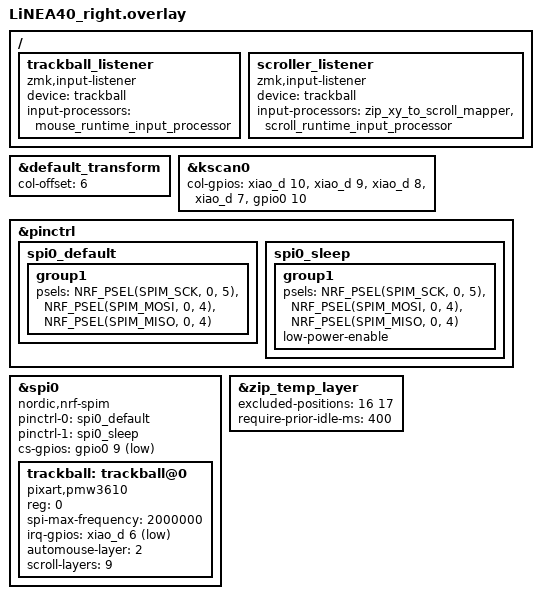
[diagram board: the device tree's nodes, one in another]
#include "LiNEA40.dtsi"
#include <input/processors.dtsi>
#include <input/processors/runtime-input-processor.dtsi>
#include <behaviors/battery_history_request.dtsi>

&default_transform {
    col-offset = <6>;
};

&kscan0 {
    col-gpios
        = <&xiao_d 10 GPIO_ACTIVE_HIGH> // col0-D10
        , <&xiao_d 9 GPIO_ACTIVE_HIGH>  // col1-D9
        , <&xiao_d 8 GPIO_ACTIVE_HIGH>  // col2-D8
        , <&xiao_d 7 GPIO_ACTIVE_HIGH>  // col3-D7
        , <&gpio0 10 GPIO_ACTIVE_HIGH>  // col4-D10 (修正済み)
        ; 
}; 

&pinctrl {
    spi0_default: spi0_default {
        group1 {
            psels = <NRF_PSEL(SPIM_SCK, 0, 5)>   // SCLK-D5
                  , <NRF_PSEL(SPIM_MOSI, 0, 4)>  // SDIO-D4
                  , <NRF_PSEL(SPIM_MISO, 0, 4)>  // SDIO-D4
                  ;
        };
    };

    spi0_sleep: spi0_sleep {
        group1 {
            psels = <NRF_PSEL(SPIM_SCK, 0, 5)>   // SCLK-D5
                  , <NRF_PSEL(SPIM_MOSI, 0, 4)>  // SDIO-D4
                  , <NRF_PSEL(SPIM_MISO, 0, 4)>  // SDIO-D4
                  ;
            low-power-enable;
        };
    };
};

&spi0 {
    status = "okay";
    compatible = "nordic,nrf-spim";
    pinctrl-0 = <&spi0_default>;
    pinctrl-1 = <&spi0_sleep>;
    pinctrl-names = "default", "sleep";
    cs-gpios = <&gpio0 9 GPIO_ACTIVE_LOW>; // NCS-NFC1

    /* トラックボールデバイス定義: ラベルを trackball に統一 */
    trackball: trackball@0 {
        status = "okay";
        compatible = "pixart,pmw3610";
        reg = <0>;
        spi-max-frequency = <2000000>;
        irq-gpios = <&xiao_d 6 (GPIO_ACTIVE_LOW | GPIO_PULL_UP)>;
        automouse-layer = <2>;
        scroll-layers = <9>;
    };
};

/ {
    trackball_listener: trackball_listener {
        compatible = "zmk,input-listener";
        device = <&trackball>;
        input-processors = <&mouse_runtime_input_processor>;
    };

    /* ここでラベル「scroller_listener」を付けて定義する */
    scroller_listener: scroller_listener {
        compatible = "zmk,input-listener";
        device = <&trackball>;
        input-processors = <&zip_xy_to_scroll_mapper &scroll_runtime_input_processor>;
    };
};




// 非マウスキーで自動マウスレイヤー解除設定
&zip_temp_layer {
    excluded-positions = <16 17>;
    require-prior-idle-ms = <400>;
};
